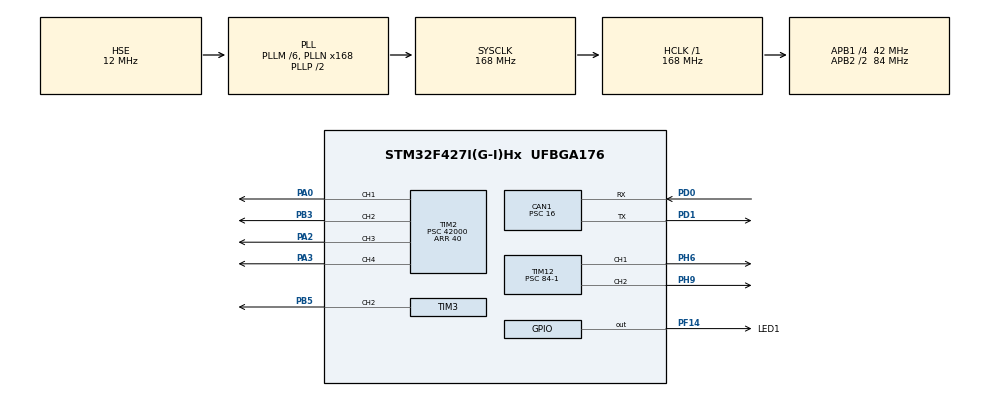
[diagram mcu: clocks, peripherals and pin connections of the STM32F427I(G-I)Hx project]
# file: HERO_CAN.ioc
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CAN1.ABOM=DISABLE
CAN1.BS1=CAN_BS1_9TQ
CAN1.BS2=CAN_BS2_3TQ
CAN1.CalculateTimeQuantum=380.95238095238096
CAN1.NART=ENABLE
CAN1.Prescaler=16
CAN1.TXFP=ENABLE
Mcu.Family=STM32F4
Mcu.Name=STM32F427I(G-I)Hx
Mcu.Package=UFBGA176
NVIC.CAN1_RX0_IRQn=true\:1\:0\:true\:false\:true\:true
NVIC.CAN1_TX_IRQn=true\:0\:0\:false\:false\:true\:true
NVIC.PriorityGroup=NVIC_PRIORITYGROUP_4
NVIC.RCC_IRQn=true\:0\:0\:false\:false\:true\:true
NVIC.TIM2_IRQn=true\:0\:0\:false\:false\:true\:true
NVIC.TIM6_DAC_IRQn=true\:0\:0\:false\:false\:true\:true
PA0/WKUP.Signal=S_TIM2_CH1_ETR
PA2.Signal=S_TIM2_CH3
PA3.Signal=S_TIM2_CH4
PB3.Signal=S_TIM2_CH2
PB5.Signal=S_TIM3_CH2
PD0.Mode=Master
PD0.Signal=CAN1_RX
PD1.Mode=Master
PD1.Signal=CAN1_TX
PF14.GPIO_Label=LED1
PF14.Signal=GPIO_Output
PH0/OSC_IN.Mode=HSE-External-Oscillator
PH0/OSC_IN.Signal=RCC_OSC_IN
PH1/OSC_OUT.Mode=HSE-External-Oscillator
PH1/OSC_OUT.Signal=RCC_OSC_OUT
PH6.Signal=S_TIM12_CH1
PH9.Signal=S_TIM12_CH2
ProjectManager.HeapSize=0x200
ProjectManager.StackSize=0x400
ProjectManager.TargetToolchain=MDK-ARM V5
RCC.48MHZClocksFreq_Value=84000000
RCC.AHBFreq_Value=168000000
RCC.APB1CLKDivider=RCC_HCLK_DIV4
RCC.APB1Freq_Value=42000000
RCC.APB1TimFreq_Value=84000000
RCC.APB2CLKDivider=RCC_HCLK_DIV2
RCC.APB2Freq_Value=84000000
RCC.APB2TimFreq_Value=168000000
RCC.CortexFreq_Value=168000000
RCC.HCLKFreq_Value=168000000
RCC.HSE_VALUE=12000000
RCC.HSI_VALUE=16000000
RCC.LSE_VALUE=32768
RCC.PLLM=8
RCC.PLLN=168
RCC.PWR_Regulator_Voltage_Scale=PWR_REGULATOR_VOLTAGE_SCALE1
RCC.SYSCLKFreq_VALUE=168000000
RCC.SYSCLKSource=RCC_SYSCLKSOURCE_PLLCLK
RCC.VCOOutputFreq_Value=336000000
SH.S_TIM12_CH1.0=TIM12_CH1,PWM Generation1 CH1
SH.S_TIM12_CH2.0=TIM12_CH2,PWM Generation2 CH2
SH.S_TIM2_CH1_ETR.0=TIM2_CH1,PWM Generation1 CH1
SH.S_TIM2_CH2.0=TIM2_CH2,PWM Generation2 CH2
SH.S_TIM2_CH3.0=TIM2_CH3,PWM Generation3 CH3
SH.S_TIM2_CH4.0=TIM2_CH4,PWM Generation4 CH4
SH.S_TIM3_CH2.0=TIM3_CH2,PWM Generation2 CH2
TIM12.Channel-PWM\ Generation1\ CH1=TIM_CHANNEL_1
TIM12.Channel-PWM\ Generation2\ CH2=TIM_CHANNEL_2
TIM12.Period=20000-1
TIM12.Prescaler=84-1
TIM2.Channel-PWM\ Generation1\ CH1=TIM_CHANNEL_1
TIM2.Channel-PWM\ Generation2\ CH2=TIM_CHANNEL_2
TIM2.Channel-PWM\ Generation3\ CH3=TIM_CHANNEL_3
TIM2.Channel-PWM\ Generation4\ CH4=TIM_CHANNEL_4
TIM2.Period=40
TIM2.Prescaler=42000
TIM2.Pulse-PWM\ Generation1\ CH1=2
TIM3.Channel-PWM\ Generation2\ CH2=TIM_CHANNEL_2
TIM3.Prescaler=83
TIM6.Period=2000
TIM6.Prescaler=42
VP_TIM2_VS_ClockSourceINT.Mode=Internal
VP_TIM6_VS_ClockSourceINT.Mode=Enable_Timer
board=custom

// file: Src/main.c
/**
  ******************************************************************************
  * @file           : main.c
  * @brief          : Main program body
  ******************************************************************************
  ** This notice applies to any and all portions of this file
  * that are not between comment pairs USER CODE BEGIN and
  * USER CODE END. Other portions of this file, whether
  * inserted by the user or by software development tools
  * are owned by their respective copyright owners.
  *
  * COPYRIGHT(c) 2018 STMicroelectronics
  *
  * Redistribution and use in source and binary forms, with or without modification,
  * are permitted provided that the following conditions are met:
  *   1. Redistributions of source code must retain the above copyright notice,
  *      this list of conditions and the following disclaimer.
  *   2. Redistributions in binary form must reproduce the above copyright notice,
  *      this list of conditions and the following disclaimer in the documentation
  *      and/or other materials provided with the distribution.
  *   3. Neither the name of STMicroelectronics nor the names of its contributors
  *      may be used to endorse or promote products derived from this software
  *      without specific prior written permission.
  *
  * THIS SOFTWARE IS PROVIDED BY THE COPYRIGHT HOLDERS AND CONTRIBUTORS "AS IS"
  * AND ANY EXPRESS OR IMPLIED WARRANTIES, INCLUDING, BUT NOT LIMITED TO, THE
  * IMPLIED WARRANTIES OF MERCHANTABILITY AND FITNESS FOR A PARTICULAR PURPOSE ARE
  * DISCLAIMED. IN NO EVENT SHALL THE COPYRIGHT HOLDER OR CONTRIBUTORS BE LIABLE
  * FOR ANY DIRECT, INDIRECT, INCIDENTAL, SPECIAL, EXEMPLARY, OR CONSEQUENTIAL
  * DAMAGES (INCLUDING, BUT NOT LIMITED TO, PROCUREMENT OF SUBSTITUTE GOODS OR
  * SERVICES; LOSS OF USE, DATA, OR PROFITS; OR BUSINESS INTERRUPTION) HOWEVER
  * CAUSED AND ON ANY THEORY OF LIABILITY, WHETHER IN CONTRACT, STRICT LIABILITY,
  * OR TORT (INCLUDING NEGLIGENCE OR OTHERWISE) ARISING IN ANY WAY OUT OF THE USE
  * OF THIS SOFTWARE, EVEN IF ADVISED OF THE POSSIBILITY OF SUCH DAMAGE.
  *
  ******************************************************************************
  */
#include "main.h"
#include "stm32f4xx_hal.h"

/* USER CODE BEGIN Includes */
#include "can.h"
/* USER CODE END Includes */

TIM_HandleTypeDef htim2;
TIM_HandleTypeDef htim3;
TIM_HandleTypeDef htim6;
TIM_HandleTypeDef htim12;

/* USER CODE BEGIN PV */
/* Private variables ---------------------------------------------------------*/
// Please remove hcan1 above if it exists.
uint8_t canRxMsg[8];
/* USER CODE END PV */

void SystemClock_Config(void);
static void MX_GPIO_Init(void);
static void MX_CAN1_Init(void);
static void MX_TIM2_Init(void);
static void MX_TIM12_Init(void);
static void MX_TIM6_Init(void);
static void MX_TIM3_Init(void);

void HAL_TIM_MspPostInit(TIM_HandleTypeDef *htim);

/* USER CODE BEGIN PFP */
/* Private function prototypes -----------------------------------------------*/

/* USER CODE END PFP */

int main(void)
{

  /* MCU Configuration----------------------------------------------------------*/

  /* Reset of all peripherals, Initializes the Flash interface and the Systick. */
  HAL_Init();

  /* Configure the system clock */
  SystemClock_Config();

  /* Initialize all configured peripherals */
  MX_GPIO_Init();
  MX_CAN1_Init();
  MX_TIM2_Init();
  MX_TIM12_Init();
  MX_TIM6_Init();
  MX_TIM3_Init();
  /* USER CODE BEGIN 2 */
	HAL_TIM_PWM_Init(&htim2);
	HAL_TIM_PWM_Init(&htim12);
	CAN_Initialize();
	HAL_TIM_Base_Start_IT(&htim6);
	HAL_TIM_Base_Start_IT(&htim2);

	Can chassis;
	Device_Initialize(&chassis,0x200, CAN_ID_STD, CAN_RTR_DATA, 8, 0x201, 8);
  /* USER CODE END 2 */

  /* Infinite loop */
  while (1)
  {

  }

}

void SystemClock_Config(void)
{

  RCC_OscInitTypeDef RCC_OscInitStruct;
  RCC_ClkInitTypeDef RCC_ClkInitStruct;

    /**Configure the main internal regulator output voltage
    */
  __HAL_RCC_PWR_CLK_ENABLE();

  __HAL_PWR_VOLTAGESCALING_CONFIG(PWR_REGULATOR_VOLTAGE_SCALE1);

    /**Initializes the CPU, AHB and APB busses clocks
    */
  RCC_OscInitStruct.OscillatorType = RCC_OSCILLATORTYPE_HSE;
  RCC_OscInitStruct.HSEState = RCC_HSE_ON;
  RCC_OscInitStruct.PLL.PLLState = RCC_PLL_ON;
  RCC_OscInitStruct.PLL.PLLSource = RCC_PLLSOURCE_HSE;
  RCC_OscInitStruct.PLL.PLLM = 6;
  RCC_OscInitStruct.PLL.PLLN = 168;
  RCC_OscInitStruct.PLL.PLLP = RCC_PLLP_DIV2;
  RCC_OscInitStruct.PLL.PLLQ = 4;
  if (HAL_RCC_OscConfig(&RCC_OscInitStruct) != HAL_OK)
  {
    _Error_Handler(__FILE__, __LINE__);
  }

    /**Initializes the CPU, AHB and APB busses clocks
    */
  RCC_ClkInitStruct.ClockType = RCC_CLOCKTYPE_HCLK|RCC_CLOCKTYPE_SYSCLK
                              |RCC_CLOCKTYPE_PCLK1|RCC_CLOCKTYPE_PCLK2;
  RCC_ClkInitStruct.SYSCLKSource = RCC_SYSCLKSOURCE_PLLCLK;
  RCC_ClkInitStruct.AHBCLKDivider = RCC_SYSCLK_DIV1;
  RCC_ClkInitStruct.APB1CLKDivider = RCC_HCLK_DIV4;
  RCC_ClkInitStruct.APB2CLKDivider = RCC_HCLK_DIV2;

  if (HAL_RCC_ClockConfig(&RCC_ClkInitStruct, FLASH_LATENCY_5) != HAL_OK)
  {
    _Error_Handler(__FILE__, __LINE__);
  }

    /**Configure the Systick interrupt time
    */
  HAL_SYSTICK_Config(HAL_RCC_GetHCLKFreq()/1000);

    /**Configure the Systick
    */
  HAL_SYSTICK_CLKSourceConfig(SYSTICK_CLKSOURCE_HCLK);

  /* SysTick_IRQn interrupt configuration */
  HAL_NVIC_SetPriority(SysTick_IRQn, 0, 0);
}

/* CAN1 init function */
static void MX_CAN1_Init(void)
{

  hcan1.Instance = CAN1;
  hcan1.Init.Prescaler = 3;
  hcan1.Init.Mode = CAN_MODE_NORMAL;
  hcan1.Init.SyncJumpWidth = CAN_SJW_1TQ;
  hcan1.Init.TimeSeg1 = CAN_BS1_9TQ;
  hcan1.Init.TimeSeg2 = CAN_BS2_4TQ;
  hcan1.Init.TimeTriggeredMode = DISABLE;
  hcan1.Init.AutoBusOff = DISABLE;
  hcan1.Init.AutoWakeUp = DISABLE;
  hcan1.Init.AutoRetransmission = DISABLE;
  hcan1.Init.ReceiveFifoLocked = DISABLE;
  hcan1.Init.TransmitFifoPriority = ENABLE;
  if (HAL_CAN_Init(&hcan1) != HAL_OK)
  {
    _Error_Handler(__FILE__, __LINE__);
  }

}

/* TIM2 init function */
static void MX_TIM2_Init(void)
{

  TIM_ClockConfigTypeDef sClockSourceConfig;
  TIM_MasterConfigTypeDef sMasterConfig;
  TIM_OC_InitTypeDef sConfigOC;

  htim2.Instance = TIM2;
  htim2.Init.Prescaler = 42000;
  htim2.Init.CounterMode = TIM_COUNTERMODE_UP;
  htim2.Init.Period = 40;
  htim2.Init.ClockDivision = TIM_CLOCKDIVISION_DIV1;
  if (HAL_TIM_Base_Init(&htim2) != HAL_OK)
  {
    _Error_Handler(__FILE__, __LINE__);
  }

  sClockSourceConfig.ClockSource = TIM_CLOCKSOURCE_INTERNAL;
  if (HAL_TIM_ConfigClockSource(&htim2, &sClockSourceConfig) != HAL_OK)
  {
    _Error_Handler(__FILE__, __LINE__);
  }

  if (HAL_TIM_PWM_Init(&htim2) != HAL_OK)
  {
    _Error_Handler(__FILE__, __LINE__);
  }

  sMasterConfig.MasterOutputTrigger = TIM_TRGO_RESET;
  sMasterConfig.MasterSlaveMode = TIM_MASTERSLAVEMODE_DISABLE;
  if (HAL_TIMEx_MasterConfigSynchronization(&htim2, &sMasterConfig) != HAL_OK)
  {
    _Error_Handler(__FILE__, __LINE__);
  }

  sConfigOC.OCMode = TIM_OCMODE_PWM1;
  sConfigOC.Pulse = 2;
  sConfigOC.OCPolarity = TIM_OCPOLARITY_HIGH;
  sConfigOC.OCFastMode = TIM_OCFAST_DISABLE;
  if (HAL_TIM_PWM_ConfigChannel(&htim2, &sConfigOC, TIM_CHANNEL_1) != HAL_OK)
  {
    _Error_Handler(__FILE__, __LINE__);
  }

  sConfigOC.Pulse = 0;
  if (HAL_TIM_PWM_ConfigChannel(&htim2, &sConfigOC, TIM_CHANNEL_2) != HAL_OK)
  {
    _Error_Handler(__FILE__, __LINE__);
  }

  if (HAL_TIM_PWM_ConfigChannel(&htim2, &sConfigOC, TIM_CHANNEL_3) != HAL_OK)
  {
    _Error_Handler(__FILE__, __LINE__);
  }

  if (HAL_TIM_PWM_ConfigChannel(&htim2, &sConfigOC, TIM_CHANNEL_4) != HAL_OK)
  {
    _Error_Handler(__FILE__, __LINE__);
  }

  HAL_TIM_MspPostInit(&htim2);

}

/* TIM3 init function */
static void MX_TIM3_Init(void)
{

  TIM_MasterConfigTypeDef sMasterConfig;
  TIM_OC_InitTypeDef sConfigOC;

  htim3.Instance = TIM3;
  htim3.Init.Prescaler = 83;
  htim3.Init.CounterMode = TIM_COUNTERMODE_UP;
  htim3.Init.Period = 0;
  htim3.Init.ClockDivision = TIM_CLOCKDIVISION_DIV1;
  if (HAL_TIM_PWM_Init(&htim3) != HAL_OK)
  {
    _Error_Handler(__FILE__, __LINE__);
  }

  sMasterConfig.MasterOutputTrigger = TIM_TRGO_RESET;
  sMasterConfig.MasterSlaveMode = TIM_MASTERSLAVEMODE_DISABLE;
  if (HAL_TIMEx_MasterConfigSynchronization(&htim3, &sMasterConfig) != HAL_OK)
  {
    _Error_Handler(__FILE__, __LINE__);
  }

  sConfigOC.OCMode = TIM_OCMODE_PWM1;
  sConfigOC.Pulse = 0;
  sConfigOC.OCPolarity = TIM_OCPOLARITY_HIGH;
  sConfigOC.OCFastMode = TIM_OCFAST_DISABLE;
  if (HAL_TIM_PWM_ConfigChannel(&htim3, &sConfigOC, TIM_CHANNEL_2) != HAL_OK)
  {
    _Error_Handler(__FILE__, __LINE__);
  }

  HAL_TIM_MspPostInit(&htim3);

}

/* TIM6 init function */
static void MX_TIM6_Init(void)
{

  TIM_MasterConfigTypeDef sMasterConfig;

  htim6.Instance = TIM6;
  htim6.Init.Prescaler = 42;
  htim6.Init.CounterMode = TIM_COUNTERMODE_UP;
  htim6.Init.Period = 2000;
  if (HAL_TIM_Base_Init(&htim6) != HAL_OK)
  {
    _Error_Handler(__FILE__, __LINE__);
  }

  sMasterConfig.MasterOutputTrigger = TIM_TRGO_RESET;
  sMasterConfig.MasterSlaveMode = TIM_MASTERSLAVEMODE_DISABLE;
  if (HAL_TIMEx_MasterConfigSynchronization(&htim6, &sMasterConfig) != HAL_OK)
  {
    _Error_Handler(__FILE__, __LINE__);
  }

}

/* TIM12 init function */
static void MX_TIM12_Init(void)
{

  TIM_OC_InitTypeDef sConfigOC;

  htim12.Instance = TIM12;
  htim12.Init.Prescaler = 84-1;
  htim12.Init.CounterMode = TIM_COUNTERMODE_UP;
  htim12.Init.Period = 20000-1;
  htim12.Init.ClockDivision = TIM_CLOCKDIVISION_DIV1;
  if (HAL_TIM_PWM_Init(&htim12) != HAL_OK)
  {
    _Error_Handler(__FILE__, __LINE__);
  }

  sConfigOC.OCMode = TIM_OCMODE_PWM1;
  sConfigOC.Pulse = 0;
  sConfigOC.OCPolarity = TIM_OCPOLARITY_HIGH;
  sConfigOC.OCFastMode = TIM_OCFAST_DISABLE;
  if (HAL_TIM_PWM_ConfigChannel(&htim12, &sConfigOC, TIM_CHANNEL_1) != HAL_OK)
  {
    _Error_Handler(__FILE__, __LINE__);
  }

  if (HAL_TIM_PWM_ConfigChannel(&htim12, &sConfigOC, TIM_CHANNEL_2) != HAL_OK)
  {
    _Error_Handler(__FILE__, __LINE__);
  }

  HAL_TIM_MspPostInit(&htim12);

}

/** Configure pins as
        * Analog
        * Input
        * Output
        * EVENT_OUT
        * EXTI
*/
static void MX_GPIO_Init(void)
{

  GPIO_InitTypeDef GPIO_InitStruct;

  /* GPIO Ports Clock Enable */
  __HAL_RCC_GPIOB_CLK_ENABLE();
  __HAL_RCC_GPIOD_CLK_ENABLE();
  __HAL_RCC_GPIOH_CLK_ENABLE();
  __HAL_RCC_GPIOA_CLK_ENABLE();
  __HAL_RCC_GPIOF_CLK_ENABLE();

  /*Configure GPIO pin Output Level */
  HAL_GPIO_WritePin(LED1_GPIO_Port, LED1_Pin, GPIO_PIN_RESET);

  /*Configure GPIO pin : LED1_Pin */
  GPIO_InitStruct.Pin = LED1_Pin;
  GPIO_InitStruct.Mode = GPIO_MODE_OUTPUT_PP;
  GPIO_InitStruct.Pull = GPIO_NOPULL;
  GPIO_InitStruct.Speed = GPIO_SPEED_FREQ_LOW;
  HAL_GPIO_Init(LED1_GPIO_Port, &GPIO_InitStruct);

}

void _Error_Handler(char *file, int line)
{
  while(1)
  {
  }
}

/************************ (C) COPYRIGHT STMicroelectronics *****END OF FILE****/
